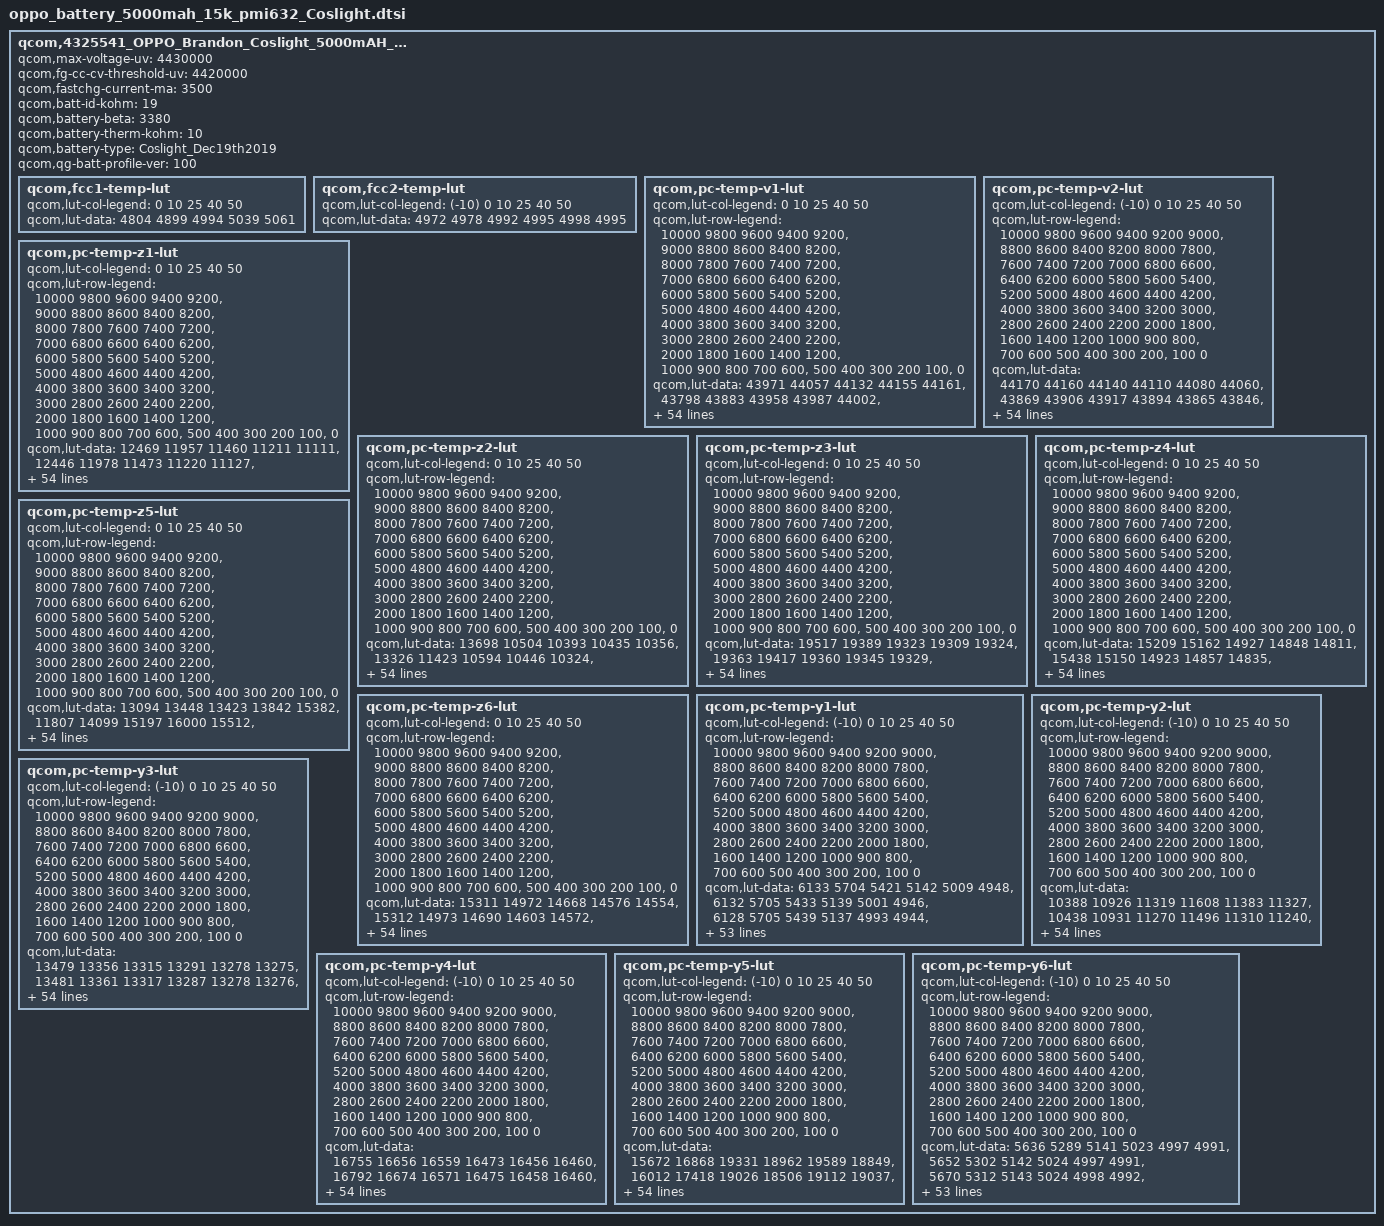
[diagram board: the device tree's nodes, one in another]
qcom,4325541_OPPO_Brandon_Coslight_5000mAH_PMI632 {
    /* 4325541_OPPO_Brandon_Coslight_5000mAH_PMI632_averaged_MasterSlave_Dec19th2019 */
    qcom,max-voltage-uv = <4430000>;
    qcom,fg-cc-cv-threshold-uv = <4420000>;
    qcom,fastchg-current-ma = <3500>;
    qcom,batt-id-kohm = <19>;
    qcom,battery-beta = <3380>;
    qcom,battery-therm-kohm = <10>;
    qcom,battery-type = "Coslight_Dec19th2019";
    qcom,qg-batt-profile-ver = <100>;

	qcom,fcc1-temp-lut {
		qcom,lut-col-legend = <0 10 25 40 50>;
		qcom,lut-data = <4804 4899 4994 5039 5061>;
	};

	qcom,fcc2-temp-lut {
		qcom,lut-col-legend = <(-10) 0 10 25 40 50>;
		qcom,lut-data = <4972 4978 4992 4995 4998 4995>;
	};

	qcom,pc-temp-v1-lut {
		qcom,lut-col-legend = <0 10 25 40 50>;
		qcom,lut-row-legend = <10000 9800 9600 9400 9200>,
			<9000 8800 8600 8400 8200>,
			<8000 7800 7600 7400 7200>,
			<7000 6800 6600 6400 6200>,
			<6000 5800 5600 5400 5200>,
			<5000 4800 4600 4400 4200>,
			<4000 3800 3600 3400 3200>,
			<3000 2800 2600 2400 2200>,
			<2000 1800 1600 1400 1200>,
			<1000 900 800 700 600>,
			<500 400 300 200 100>,
			<0>;
		qcom,lut-data = <43971 44057 44132 44155 44161>,
			<43798 43883 43958 43987 44002>,
			<43566 43688 43770 43806 43822>,
			<43320 43475 43569 43614 43628>,
			<43084 43249 43353 43404 43424>,
			<42847 43013 43128 43181 43208>,
			<42612 42767 42894 42952 42982>,
			<42376 42525 42653 42714 42747>,
			<42143 42286 42413 42475 42509>,
			<41914 42050 42172 42235 42269>,
			<41688 41818 41934 41996 42030>,
			<41469 41591 41699 41760 41793>,
			<41257 41370 41470 41529 41559>,
			<41051 41160 41247 41302 41329>,
			<40843 40952 41031 41081 41105>,
			<40632 40743 40822 40867 40886>,
			<40428 40535 40616 40661 40680>,
			<40241 40339 40416 40461 40482>,
			<40065 40167 40225 40266 40289>,
			<39887 39991 40046 40084 40103>,
			<39713 39756 39848 39894 39912>,
			<39534 39448 39584 39652 39680>,
			<39324 39205 39308 39372 39407>,
			<39077 39063 39124 39163 39189>,
			<38891 38952 38994 39022 39041>,
			<38794 38848 38878 38901 38918>,
			<38723 38754 38761 38781 38797>,
			<38655 38666 38653 38668 38684>,
			<38590 38581 38557 38567 38579>,
			<38530 38501 38468 38474 38479>,
			<38475 38430 38389 38390 38388>,
			<38424 38365 38318 38311 38305>,
			<38377 38308 38254 38238 38228>,
			<38336 38258 38195 38169 38155>,
			<38298 38213 38141 38107 38084>,
			<38259 38170 38090 38045 38013>,
			<38220 38132 38043 37985 37944>,
			<38173 38088 37994 37925 37874>,
			<38101 38019 37925 37847 37790>,
			<38007 37920 37825 37745 37684>,
			<37898 37809 37713 37629 37567>,
			<37762 37681 37595 37509 37442>,
			<37613 37537 37463 37377 37306>,
			<37445 37370 37301 37219 37151>,
			<37302 37230 37162 37088 37030>,
			<37213 37141 37076 37014 36957>,
			<37188 37120 37054 36990 36935>,
			<37168 37103 37038 36973 36919>,
			<37136 37080 37023 36956 36896>,
			<37076 37025 36959 36877 36805>,
			<36839 36769 36675 36569 36481>,
			<36378 36311 36224 36117 36027>,
			<35790 35723 35638 35532 35441>,
			<34987 34916 34832 34728 34635>,
			<33702 33635 33569 33469 33375>,
			<30000 30000 30000 30000 30000>;
	};

	qcom,pc-temp-v2-lut {
		qcom,lut-col-legend = <(-10) 0 10 25 40 50>;
		qcom,lut-row-legend = <10000 9800 9600 9400 9200 9000>,
			<8800 8600 8400 8200 8000 7800>,
			<7600 7400 7200 7000 6800 6600>,
			<6400 6200 6000 5800 5600 5400>,
			<5200 5000 4800 4600 4400 4200>,
			<4000 3800 3600 3400 3200 3000>,
			<2800 2600 2400 2200 2000 1800>,
			<1600 1400 1200 1000 900 800>,
			<700 600 500 400 300 200>,
			<100 0>;
		qcom,lut-data = <44170 44160 44140 44110 44080 44060>,
			<43869 43906 43917 43894 43865 43846>,
			<43589 43659 43692 43676 43649 43631>,
			<43330 43422 43469 43457 43433 43416>,
			<43095 43194 43247 43237 43216 43201>,
			<42861 42964 43019 43012 42994 42980>,
			<42615 42721 42782 42776 42760 42748>,
			<42368 42473 42539 42535 42521 42509>,
			<42136 42229 42298 42296 42282 42272>,
			<41922 41985 42055 42057 42043 42033>,
			<41698 41749 41817 41822 41806 41797>,
			<41431 41522 41583 41587 41572 41564>,
			<41154 41302 41354 41357 41343 41335>,
			<40938 41092 41132 41131 41118 41111>,
			<40783 40893 40917 40911 40898 40891>,
			<40602 40684 40706 40698 40685 40679>,
			<40291 40446 40501 40494 40482 40477>,
			<39905 40190 40294 40294 40285 40281>,
			<39624 39935 40060 40094 40091 40089>,
			<39425 39672 39789 39895 39905 39904>,
			<39236 39428 39533 39682 39703 39704>,
			<39016 39219 39311 39426 39445 39450>,
			<38794 39032 39111 39164 39177 39184>,
			<38613 38862 38938 38969 38982 38990>,
			<38460 38708 38788 38819 38834 38842>,
			<38337 38568 38653 38689 38705 38712>,
			<38248 38439 38529 38568 38584 38590>,
			<38178 38320 38415 38458 38474 38479>,
			<38115 38207 38311 38357 38374 38377>,
			<38058 38093 38213 38263 38281 38281>,
			<38005 38003 38122 38177 38196 38193>,
			<37951 37945 38032 38096 38121 38117>,
			<37899 37900 37949 38020 38049 38044>,
			<37843 37860 37880 37948 37971 37962>,
			<37785 37825 37823 37881 37889 37870>,
			<37724 37786 37771 37810 37800 37772>,
			<37657 37734 37723 37731 37698 37663>,
			<37585 37668 37676 37647 37590 37549>,
			<37504 37591 37614 37563 37494 37449>,
			<37407 37501 37534 37482 37409 37362>,
			<37307 37397 37438 37393 37319 37270>,
			<37209 37269 37318 37285 37213 37163>,
			<37113 37130 37182 37164 37098 37045>,
			<37020 37014 37042 37023 36960 36904>,
			<36932 36912 36927 36921 36872 36818>,
			<36842 36827 36852 36878 36834 36783>,
			<36786 36784 36821 36860 36824 36773>,
			<36719 36720 36792 36841 36807 36756>,
			<36624 36628 36739 36812 36774 36721>,
			<36493 36488 36633 36720 36655 36571>,
			<36295 36249 36359 36403 36285 36186>,
			<35945 35870 35878 35902 35770 35670>,
			<35365 35295 35201 35236 35098 34990>,
			<34502 34434 34287 34328 34151 34042>,
			<33097 32984 32797 32911 32702 32622>,
			<28862 28432 27905 27825 27876 27931>;
	};

	qcom,pc-temp-z1-lut {
		qcom,lut-col-legend = <0 10 25 40 50>;
		qcom,lut-row-legend = <10000 9800 9600 9400 9200>,
			<9000 8800 8600 8400 8200>,
			<8000 7800 7600 7400 7200>,
			<7000 6800 6600 6400 6200>,
			<6000 5800 5600 5400 5200>,
			<5000 4800 4600 4400 4200>,
			<4000 3800 3600 3400 3200>,
			<3000 2800 2600 2400 2200>,
			<2000 1800 1600 1400 1200>,
			<1000 900 800 700 600>,
			<500 400 300 200 100>,
			<0>;
		qcom,lut-data = <12469 11957 11460 11211 11111>,
			<12446 11978 11473 11220 11127>,
			<12471 11982 11479 11224 11135>,
			<12493 11978 11479 11224 11138>,
			<12490 11973 11471 11223 11138>,
			<12479 11963 11463 11220 11137>,
			<12473 11948 11455 11217 11136>,
			<12460 11935 11446 11212 11133>,
			<12444 11924 11438 11208 11130>,
			<12426 11913 11431 11206 11130>,
			<12394 11899 11426 11205 11130>,
			<12370 11884 11424 11203 11129>,
			<12360 11875 11423 11202 11127>,
			<12353 11871 11422 11201 11127>,
			<12344 11867 11421 11200 11127>,
			<12334 11863 11420 11200 11127>,
			<12325 11858 11420 11200 11127>,
			<12323 11856 11419 11199 11127>,
			<12323 11855 11420 11199 11127>,
			<12324 11854 11421 11200 11128>,
			<12322 11856 11422 11201 11130>,
			<12319 11861 11423 11201 11130>,
			<12320 11866 11425 11202 11129>,
			<12325 11869 11428 11203 11129>,
			<12328 11872 11432 11205 11131>,
			<12330 11874 11437 11207 11133>,
			<12332 11877 11442 11211 11136>,
			<12333 11879 11447 11214 11140>,
			<12335 11881 11452 11218 11143>,
			<12337 11886 11456 11222 11146>,
			<12341 11888 11459 11226 11149>,
			<12348 11894 11464 11229 11153>,
			<12353 11899 11470 11233 11157>,
			<12361 11900 11474 11237 11161>,
			<12369 11902 11479 11241 11164>,
			<12374 11904 11484 11246 11167>,
			<12377 11909 11488 11249 11170>,
			<12382 11916 11492 11253 11174>,
			<12395 11925 11497 11256 11177>,
			<12411 11936 11504 11261 11180>,
			<12419 11946 11512 11266 11183>,
			<12425 11956 11520 11270 11187>,
			<12431 11967 11528 11275 11190>,
			<12438 11980 11536 11279 11191>,
			<12469 12000 11548 11285 11196>,
			<12470 11990 11559 11289 11197>,
			<12475 11994 11555 11290 11199>,
			<12472 11995 11560 11290 11200>,
			<12463 11996 11563 11294 11203>,
			<12479 12000 11574 11300 11208>,
			<12488 12027 11579 11306 11215>,
			<12499 12033 11586 11315 11219>,
			<12510 12034 11597 11322 11228>,
			<12527 12064 11611 11338 11242>,
			<12527 12064 11611 11338 11242>,
			<12527 12064 11611 11338 11242>;
	};

	qcom,pc-temp-z2-lut {
		qcom,lut-col-legend = <0 10 25 40 50>;
		qcom,lut-row-legend = <10000 9800 9600 9400 9200>,
			<9000 8800 8600 8400 8200>,
			<8000 7800 7600 7400 7200>,
			<7000 6800 6600 6400 6200>,
			<6000 5800 5600 5400 5200>,
			<5000 4800 4600 4400 4200>,
			<4000 3800 3600 3400 3200>,
			<3000 2800 2600 2400 2200>,
			<2000 1800 1600 1400 1200>,
			<1000 900 800 700 600>,
			<500 400 300 200 100>,
			<0>;
		qcom,lut-data = <13698 10504 10393 10435 10356>,
			<13326 11423 10594 10446 10324>,
			<11592 11584 10717 10457 10394>,
			<10391 11326 10726 10463 10451>,
			<10299 11020 10685 10497 10433>,
			<10277 10768 10642 10539 10387>,
			<10260 10526 10602 10527 10339>,
			<10242 10437 10561 10473 10270>,
			<10228 10407 10531 10429 10215>,
			<10218 10392 10503 10407 10188>,
			<10209 10392 10490 10386 10168>,
			<10204 10393 10502 10345 10169>,
			<10207 10397 10525 10280 10192>,
			<10213 10422 10542 10254 10211>,
			<10221 10456 10556 10267 10229>,
			<10234 10477 10573 10288 10252>,
			<10252 10494 10612 10310 10260>,
			<10277 10509 10656 10334 10265>,
			<10310 10522 10670 10355 10277>,
			<10332 10537 10671 10370 10325>,
			<10343 10565 10675 10391 10390>,
			<10352 10618 10721 10497 10425>,
			<10366 10645 10785 10723 10451>,
			<10387 10619 10803 10800 10479>,
			<10399 10579 10803 10725 10516>,
			<10400 10573 10802 10646 10552>,
			<10400 10585 10804 10657 10563>,
			<10401 10597 10805 10718 10550>,
			<10407 10605 10796 10721 10541>,
			<10414 10610 10761 10649 10512>,
			<10421 10615 10738 10584 10466>,
			<10430 10620 10736 10568 10412>,
			<10435 10627 10737 10558 10345>,
			<10438 10636 10746 10556 10324>,
			<10440 10649 10783 10558 10340>,
			<10442 10660 10818 10561 10369>,
			<10449 10668 10835 10587 10416>,
			<10453 10677 10852 10655 10490>,
			<10452 10690 10880 10746 10564>,
			<10449 10708 10935 10911 10688>,
			<10446 10715 10966 11018 10785>,
			<10436 10702 10957 10966 10826>,
			<10432 10689 10943 10883 10854>,
			<10441 10682 10932 10881 10751>,
			<10580 10780 10941 10814 10644>,
			<10591 10836 10931 10726 10549>,
			<10511 10796 10944 10640 10585>,
			<10312 10720 10893 10671 10558>,
			<10311 10735 10839 10717 10632>,
			<10278 10722 10910 10839 10699>,
			<10300 10726 10906 10660 10431>,
			<10184 10666 10796 10370 10199>,
			<10022 10589 10796 10323 10181>,
			<9865 10479 10703 10227 10094>,
			<9865 10479 10703 10227 10094>,
			<9865 10479 10703 10227 10094>;
	};

	qcom,pc-temp-z3-lut {
		qcom,lut-col-legend = <0 10 25 40 50>;
		qcom,lut-row-legend = <10000 9800 9600 9400 9200>,
			<9000 8800 8600 8400 8200>,
			<8000 7800 7600 7400 7200>,
			<7000 6800 6600 6400 6200>,
			<6000 5800 5600 5400 5200>,
			<5000 4800 4600 4400 4200>,
			<4000 3800 3600 3400 3200>,
			<3000 2800 2600 2400 2200>,
			<2000 1800 1600 1400 1200>,
			<1000 900 800 700 600>,
			<500 400 300 200 100>,
			<0>;
		qcom,lut-data = <19517 19389 19323 19309 19324>,
			<19363 19417 19360 19345 19329>,
			<19500 19440 19389 19359 19348>,
			<19629 19475 19407 19369 19366>,
			<19655 19502 19420 19382 19374>,
			<19668 19513 19426 19394 19380>,
			<19672 19520 19426 19397 19384>,
			<19671 19522 19426 19398 19387>,
			<19669 19522 19426 19398 19388>,
			<19668 19521 19425 19395 19387>,
			<19668 19519 19425 19391 19383>,
			<19666 19516 19421 19387 19380>,
			<19660 19512 19415 19380 19377>,
			<19650 19500 19410 19375 19374>,
			<19648 19489 19403 19370 19372>,
			<19652 19488 19400 19366 19369>,
			<19654 19488 19399 19363 19365>,
			<19644 19488 19398 19362 19358>,
			<19617 19483 19396 19360 19354>,
			<19606 19477 19393 19357 19352>,
			<19621 19483 19391 19355 19350>,
			<19640 19511 19398 19357 19350>,
			<19647 19527 19407 19362 19351>,
			<19651 19516 19408 19364 19351>,
			<19653 19499 19400 19360 19352>,
			<19647 19495 19394 19357 19354>,
			<19635 19495 19402 19364 19359>,
			<19629 19495 19414 19381 19372>,
			<19625 19499 19417 19387 19379>,
			<19622 19505 19418 19383 19380>,
			<19621 19507 19417 19379 19380>,
			<19620 19506 19414 19377 19377>,
			<19618 19504 19410 19375 19371>,
			<19616 19502 19408 19371 19365>,
			<19613 19499 19405 19366 19356>,
			<19612 19496 19403 19360 19350>,
			<19610 19493 19398 19355 19346>,
			<19608 19489 19394 19351 19344>,
			<19602 19486 19393 19350 19343>,
			<19593 19481 19392 19353 19344>,
			<19587 19477 19392 19355 19345>,
			<19583 19474 19389 19356 19351>,
			<19576 19470 19385 19357 19357>,
			<19558 19460 19379 19357 19356>,
			<19497 19430 19367 19352 19350>,
			<19463 19417 19360 19335 19335>,
			<19418 19401 19358 19332 19326>,
			<19351 19371 19352 19332 19320>,
			<19345 19344 19329 19319 19314>,
			<19341 19332 19329 19321 19316>,
			<19342 19337 19336 19348 19345>,
			<19343 19331 19339 19355 19348>,
			<19341 19319 19328 19345 19343>,
			<19340 19320 19336 19341 19340>,
			<19340 19320 19336 19341 19340>,
			<19340 19320 19336 19341 19340>;
	};

	qcom,pc-temp-z4-lut {
		qcom,lut-col-legend = <0 10 25 40 50>;
		qcom,lut-row-legend = <10000 9800 9600 9400 9200>,
			<9000 8800 8600 8400 8200>,
			<8000 7800 7600 7400 7200>,
			<7000 6800 6600 6400 6200>,
			<6000 5800 5600 5400 5200>,
			<5000 4800 4600 4400 4200>,
			<4000 3800 3600 3400 3200>,
			<3000 2800 2600 2400 2200>,
			<2000 1800 1600 1400 1200>,
			<1000 900 800 700 600>,
			<500 400 300 200 100>,
			<0>;
		qcom,lut-data = <15209 15162 14927 14848 14811>,
			<15438 15150 14923 14857 14835>,
			<15383 15122 14914 14848 14828>,
			<15306 15057 14898 14836 14818>,
			<15228 14991 14862 14815 14804>,
			<15140 14948 14828 14789 14784>,
			<15070 14912 14806 14770 14767>,
			<15018 14881 14786 14754 14751>,
			<14974 14852 14767 14740 14737>,
			<14936 14827 14749 14724 14724>,
			<14901 14805 14734 14712 14712>,
			<14874 14785 14724 14709 14705>,
			<14853 14772 14717 14706 14701>,
			<14836 14763 14712 14704 14697>,
			<14819 14757 14708 14701 14693>,
			<14797 14753 14705 14697 14690>,
			<14784 14750 14700 14692 14686>,
			<14788 14747 14695 14685 14683>,
			<14799 14741 14694 14683 14681>,
			<14804 14737 14696 14684 14682>,
			<14788 14749 14699 14687 14684>,
			<14770 14799 14739 14713 14703>,
			<14784 14834 14797 14776 14766>,
			<14847 14843 14808 14799 14797>,
			<14887 14849 14807 14796 14790>,
			<14885 14848 14805 14791 14778>,
			<14879 14835 14791 14775 14761>,
			<14873 14820 14767 14745 14736>,
			<14863 14805 14752 14727 14717>,
			<14852 14790 14741 14719 14705>,
			<14843 14781 14733 14712 14695>,
			<14834 14776 14727 14704 14689>,
			<14825 14771 14723 14696 14683>,
			<14817 14769 14720 14694 14682>,
			<14810 14767 14718 14694 14683>,
			<14804 14765 14717 14694 14684>,
			<14798 14762 14717 14694 14685>,
			<14792 14760 14716 14695 14685>,
			<14787 14758 14717 14696 14687>,
			<14782 14756 14723 14703 14696>,
			<14774 14752 14726 14708 14704>,
			<14762 14741 14720 14704 14698>,
			<14748 14728 14711 14698 14688>,
			<14735 14718 14707 14697 14692>,
			<14707 14690 14689 14686 14684>,
			<14715 14674 14670 14674 14671>,
			<14759 14679 14660 14669 14670>,
			<14828 14703 14653 14654 14659>,
			<14830 14726 14662 14646 14642>,
			<14829 14737 14660 14637 14633>,
			<14829 14742 14678 14647 14649>,
			<14841 14758 14682 14650 14656>,
			<14851 14773 14695 14660 14662>,
			<14863 14776 14686 14666 14665>,
			<14863 14776 14686 14666 14665>,
			<14863 14776 14686 14666 14665>;
	};

	qcom,pc-temp-z5-lut {
		qcom,lut-col-legend = <0 10 25 40 50>;
		qcom,lut-row-legend = <10000 9800 9600 9400 9200>,
			<9000 8800 8600 8400 8200>,
			<8000 7800 7600 7400 7200>,
			<7000 6800 6600 6400 6200>,
			<6000 5800 5600 5400 5200>,
			<5000 4800 4600 4400 4200>,
			<4000 3800 3600 3400 3200>,
			<3000 2800 2600 2400 2200>,
			<2000 1800 1600 1400 1200>,
			<1000 900 800 700 600>,
			<500 400 300 200 100>,
			<0>;
		qcom,lut-data = <13094 13448 13423 13842 15382>,
			<11807 14099 15197 16000 15512>,
			<13612 14640 16588 16805 17064>,
			<15521 15407 17483 17483 18517>,
			<16260 16215 18159 18634 19230>,
			<16744 16988 18568 19808 19850>,
			<17179 17811 18753 20291 20413>,
			<17602 18407 18912 20649 20964>,
			<18065 18917 19224 20867 21529>,
			<18730 19480 19902 21457 22190>,
			<19678 20278 20600 22114 22884>,
			<20479 21216 21210 22120 23419>,
			<20989 21603 21782 21813 23838>,
			<21539 21654 22153 21673 24320>,
			<22735 21704 22275 21660 25319>,
			<26503 22391 22417 21797 26346>,
			<29510 24275 23364 22469 26369>,
			<28273 25150 24725 23718 25772>,
			<24894 24614 25273 24497 25449>,
			<23722 23950 25478 24945 26588>,
			<30472 27576 25779 25228 28085>,
			<39765 42562 27216 24998 27527>,
			<44506 51304 29046 24114 24379>,
			<47867 43689 28467 23009 21555>,
			<49305 31990 23814 20305 19385>,
			<45493 28329 20814 18041 17911>,
			<38731 27146 21791 18901 18362>,
			<35608 26676 23646 21352 20404>,
			<34198 27819 25056 22586 22206>,
			<33499 30321 26454 22892 24048>,
			<33714 32385 27778 23215 25796>,
			<34401 34215 28894 24300 26875>,
			<35000 35718 29943 26052 27714>,
			<35758 36821 31215 27033 28076>,
			<36465 37750 33026 27576 27926>,
			<36982 38165 33987 27841 27725>,
			<38380 38244 33645 27697 27885>,
			<39246 38171 32974 27397 28195>,
			<38784 37822 32472 27343 28191>,
			<38006 37075 32102 27589 27171>,
			<37776 36517 31586 27777 26309>,
			<37458 36259 30208 27095 27209>,
			<36710 35795 28332 25973 28531>,
			<34352 33675 26283 25593 27843>,
			<30656 33053 26586 25413 26087>,
			<23675 32735 27458 21549 21268>,
			<17903 25194 27611 21224 19273>,
			<13204 18941 26512 23749 19190>,
			<13022 15270 19344 22297 21774>,
			<12977 14472 19352 23973 24935>,
			<13121 14733 18310 27173 27209>,
			<12911 13916 17407 25373 24224>,
			<12635 13203 15273 19867 19916>,
			<12381 13033 15874 17650 17728>,
			<12381 13033 15874 17650 17728>,
			<12381 13033 15874 17650 17728>;
	};

	qcom,pc-temp-z6-lut {
		qcom,lut-col-legend = <0 10 25 40 50>;
		qcom,lut-row-legend = <10000 9800 9600 9400 9200>,
			<9000 8800 8600 8400 8200>,
			<8000 7800 7600 7400 7200>,
			<7000 6800 6600 6400 6200>,
			<6000 5800 5600 5400 5200>,
			<5000 4800 4600 4400 4200>,
			<4000 3800 3600 3400 3200>,
			<3000 2800 2600 2400 2200>,
			<2000 1800 1600 1400 1200>,
			<1000 900 800 700 600>,
			<500 400 300 200 100>,
			<0>;
		qcom,lut-data = <15311 14972 14668 14576 14554>,
			<15312 14973 14690 14603 14572>,
			<15320 14965 14702 14610 14582>,
			<15325 14945 14701 14612 14589>,
			<15305 14922 14691 14609 14587>,
			<15249 14901 14679 14603 14582>,
			<15200 14881 14668 14598 14578>,
			<15165 14862 14658 14591 14573>,
			<15134 14843 14649 14585 14567>,
			<15107 14826 14640 14577 14561>,
			<15084 14811 14632 14570 14554>,
			<15063 14798 14624 14564 14549>,
			<15044 14786 14618 14559 14545>,
			<15026 14775 14612 14555 14542>,
			<15012 14766 14607 14550 14538>,
			<15001 14762 14603 14546 14535>,
			<14991 14760 14600 14542 14530>,
			<14983 14758 14597 14538 14525>,
			<14975 14753 14596 14536 14522>,
			<14972 14748 14596 14535 14521>,
			<14974 14757 14595 14535 14521>,
			<14977 14796 14616 14546 14528>,
			<14989 14818 14647 14577 14556>,
			<15020 14816 14652 14588 14570>,
			<15038 14813 14650 14586 14568>,
			<15035 14809 14647 14582 14564>,
			<15028 14805 14644 14579 14561>,
			<15023 14801 14642 14576 14557>,
			<15019 14799 14639 14573 14553>,
			<15015 14797 14635 14568 14550>,
			<15012 14795 14632 14563 14546>,
			<15009 14793 14629 14560 14542>,
			<15006 14792 14625 14556 14537>,
			<15004 14791 14624 14553 14533>,
			<15001 14790 14623 14550 14530>,
			<15001 14789 14622 14548 14527>,
			<15001 14788 14620 14546 14525>,
			<15001 14788 14618 14544 14524>,
			<15001 14788 14619 14544 14524>,
			<15001 14789 14622 14549 14528>,
			<15002 14789 14625 14552 14532>,
			<15002 14787 14622 14551 14532>,
			<15002 14783 14617 14550 14532>,
			<14998 14780 14615 14550 14533>,
			<14974 14764 14604 14544 14528>,
			<14965 14754 14595 14531 14514>,
			<14962 14750 14589 14526 14510>,
			<14958 14746 14584 14520 14502>,
			<14959 14743 14577 14510 14491>,
			<14961 14746 14578 14508 14489>,
			<14970 14756 14592 14528 14512>,
			<14983 14764 14597 14535 14521>,
			<14995 14772 14601 14537 14524>,
			<15014 14784 14607 14542 14527>,
			<15014 14784 14607 14542 14527>,
			<15014 14784 14607 14542 14527>;
	};

	qcom,pc-temp-y1-lut {
		qcom,lut-col-legend = <(-10) 0 10 25 40 50>;
		qcom,lut-row-legend = <10000 9800 9600 9400 9200 9000>,
			<8800 8600 8400 8200 8000 7800>,
			<7600 7400 7200 7000 6800 6600>,
			<6400 6200 6000 5800 5600 5400>,
			<5200 5000 4800 4600 4400 4200>,
			<4000 3800 3600 3400 3200 3000>,
			<2800 2600 2400 2200 2000 1800>,
			<1600 1400 1200 1000 900 800>,
			<700 600 500 400 300 200>,
			<100 0>;
		qcom,lut-data = <6133 5704 5421 5142 5009 4948>,
			<6132 5705 5433 5139 5001 4946>,
			<6128 5705 5439 5137 4993 4944>,
			<6124 5705 5440 5133 4987 4942>,
			<6120 5706 5439 5130 4982 4940>,
			<6117 5706 5436 5127 4980 4938>,
			<6111 5707 5429 5125 4981 4935>,
			<6101 5708 5420 5122 4983 4933>,
			<6102 5707 5414 5121 4983 4933>,
			<6118 5704 5410 5119 4982 4935>,
			<6129 5700 5408 5118 4982 4936>,
			<6127 5698 5406 5117 4980 4935>,
			<6122 5696 5405 5115 4979 4934>,
			<6123 5695 5403 5115 4978 4934>,
			<6133 5694 5400 5115 4977 4935>,
			<6140 5693 5398 5115 4977 4936>,
			<6134 5692 5400 5115 4977 4936>,
			<6122 5692 5403 5115 4978 4935>,
			<6120 5692 5403 5115 4979 4935>,
			<6130 5697 5401 5116 4981 4936>,
			<6137 5700 5400 5118 4982 4936>,
			<6129 5701 5401 5119 4982 4936>,
			<6113 5701 5403 5122 4982 4936>,
			<6108 5701 5404 5125 4983 4937>,
			<6115 5698 5405 5128 4985 4938>,
			<6121 5697 5406 5131 4987 4940>,
			<6115 5703 5407 5135 4988 4940>,
			<6105 5712 5411 5139 4989 4941>,
			<6103 5716 5415 5142 4991 4942>,
			<6119 5716 5422 5144 4993 4945>,
			<6133 5714 5427 5146 4997 4948>,
			<6125 5712 5428 5152 5000 4950>,
			<6107 5711 5429 5159 5004 4953>,
			<6101 5710 5430 5163 5007 4955>,
			<6095 5705 5435 5165 5010 4959>,
			<6091 5701 5438 5167 5012 4961>,
			<6090 5707 5439 5171 5015 4963>,
			<6089 5720 5440 5176 5017 4964>,
			<6088 5724 5442 5179 5018 4966>,
			<6089 5718 5445 5180 5019 4968>,
			<6089 5711 5449 5183 5020 4970>,
			<6090 5708 5463 5188 5024 4971>,
			<6093 5704 5476 5194 5029 4973>,
			<6096 5710 5470 5195 5031 4976>,
			<6097 5714 5465 5199 5035 4978>,
			<6101 5726 5475 5203 5040 4982>,
			<6145 5729 5473 5207 5038 4981>,
			<6149 5722 5478 5208 5036 4980>,
			<6129 5732 5482 5210 5036 4981>,
			<6128 5745 5473 5209 5037 4983>,
			<6167 5737 5478 5212 5039 4986>,
			<6208 5739 5485 5222 5046 4990>,
			<6259 5778 5493 5233 5054 4996>,
			<6345 5816 5514 5249 5060 5003>,
			<6345 5816 5514 5249 5060 5003>,
			<6345 5816 5514 5249 5060 5003>;
	};

	qcom,pc-temp-y2-lut {
		qcom,lut-col-legend = <(-10) 0 10 25 40 50>;
		qcom,lut-row-legend = <10000 9800 9600 9400 9200 9000>,
			<8800 8600 8400 8200 8000 7800>,
			<7600 7400 7200 7000 6800 6600>,
			<6400 6200 6000 5800 5600 5400>,
			<5200 5000 4800 4600 4400 4200>,
			<4000 3800 3600 3400 3200 3000>,
			<2800 2600 2400 2200 2000 1800>,
			<1600 1400 1200 1000 900 800>,
			<700 600 500 400 300 200>,
			<100 0>;
		qcom,lut-data = <10388 10926 11319 11608 11383 11327>,
			<10438 10931 11270 11496 11310 11240>,
			<10488 10924 11221 11381 11212 11137>,
			<10535 10912 11175 11279 11112 11033>,
			<10576 10898 11133 11203 11030 10946>,
			<10607 10889 11097 11169 10990 10894>,
			<10633 10879 11063 11182 10986 10872>,
			<10652 10867 11035 11207 10988 10858>,
			<10654 10868 11026 11202 10972 10836>,
			<10645 10884 11022 11166 10920 10799>,
			<10639 10901 11021 11141 10887 10774>,
			<10716 10908 11036 11150 10887 10781>,
			<10849 10914 11068 11167 10889 10796>,
			<10866 10946 11102 11168 10895 10799>,
			<10776 11079 11140 11156 10922 10798>,
			<10709 11173 11188 11148 10949 10797>,
			<10744 11160 11282 11198 10975 10833>,
			<10810 11137 11382 11305 11021 10913>,
			<10828 11133 11400 11421 11119 11014>,
			<10827 11148 11392 11576 11366 11168>,
			<10825 11159 11383 11660 11516 11266>,
			<10533 11157 11380 11619 11423 11262>,
			<9962 11153 11382 11547 11276 11240>,
			<9771 11153 11390 11513 11255 11249>,
			<9744 11162 11411 11497 11298 11293>,
			<9726 11169 11428 11496 11352 11336>,
			<9710 11151 11436 11557 11406 11360>,
			<9696 11113 11443 11647 11461 11385>,
			<9688 11088 11447 11667 11517 11426>,
			<9683 11073 11453 11660 11612 11495>,
			<9680 11057 11455 11656 11688 11562>,
			<9677 11027 11443 11698 11750 11633>,
			<9674 10984 11420 11762 11811 11704>,
			<9672 10945 11397 11771 11811 11731>,
			<9670 10913 11371 11745 11746 11763>,
			<9668 10865 11346 11712 11666 11767>,
			<9667 10615 11321 11671 11563 11659>,
			<9666 10152 11289 11628 11459 11498>,
			<9664 9906 11246 11603 11438 11439>,
			<9663 9785 11176 11577 11438 11428>,
			<9663 9715 11096 11563 11438 11428>,
			<9662 9695 11016 11547 11444 11407>,
			<9661 9685 10923 11517 11442 11355>,
			<9660 9679 10811 11452 11337 11185>,
			<9658 9673 10465 11357 11161 10951>,
			<9657 9669 10218 11298 11059 10917>,
			<9657 9667 10170 11321 11092 10921>,
			<9656 9665 10320 11271 11120 10954>,
			<9655 9663 10308 11318 11189 11030>,
			<9654 9661 10481 11335 11169 10939>,
			<9652 9659 9965 11252 11080 10866>,
			<9650 9656 9768 11155 10934 10777>,
			<9649 9653 9689 11036 10906 10711>,
			<9649 9651 9665 10950 10719 10616>,
			<9649 9651 9665 10950 10719 10616>,
			<9649 9651 9665 10950 10719 10616>;
	};

	qcom,pc-temp-y3-lut {
		qcom,lut-col-legend = <(-10) 0 10 25 40 50>;
		qcom,lut-row-legend = <10000 9800 9600 9400 9200 9000>,
			<8800 8600 8400 8200 8000 7800>,
			<7600 7400 7200 7000 6800 6600>,
			<6400 6200 6000 5800 5600 5400>,
			<5200 5000 4800 4600 4400 4200>,
			<4000 3800 3600 3400 3200 3000>,
			<2800 2600 2400 2200 2000 1800>,
			<1600 1400 1200 1000 900 800>,
			<700 600 500 400 300 200>,
			<100 0>;
		qcom,lut-data = <13479 13356 13315 13291 13278 13275>,
			<13481 13361 13317 13287 13278 13276>,
			<13484 13367 13319 13285 13278 13277>,
			<13486 13372 13321 13284 13279 13278>,
			<13488 13376 13323 13284 13280 13279>,
			<13489 13379 13325 13284 13280 13280>,
			<13490 13381 13327 13285 13281 13280>,
			<13490 13382 13329 13286 13283 13281>,
			<13491 13382 13330 13289 13284 13281>,
			<13495 13382 13330 13293 13285 13282>,
			<13498 13382 13330 13295 13285 13283>,
			<13479 13382 13330 13296 13286 13283>,
			<13447 13383 13331 13297 13286 13284>,
			<13439 13382 13331 13297 13287 13285>,
			<13440 13376 13330 13296 13287 13285>,
			<13441 13371 13330 13295 13287 13286>,
			<13436 13370 13330 13297 13288 13287>,
			<13427 13369 13329 13300 13290 13290>,
			<13420 13366 13328 13301 13292 13291>,
			<13416 13358 13324 13301 13293 13291>,
			<13411 13350 13318 13300 13294 13291>,
			<13402 13346 13314 13296 13288 13286>,
			<13393 13343 13310 13288 13280 13278>,
			<13390 13341 13308 13286 13278 13277>,
			<13390 13338 13307 13284 13278 13277>,
			<13391 13336 13306 13284 13279 13278>,
			<13396 13335 13305 13284 13278 13278>,
			<13408 13334 13305 13284 13277 13277>,
			<13422 13331 13305 13284 13276 13277>,
			<13441 13321 13304 13284 13276 13276>,
			<13464 13313 13304 13284 13277 13275>,
			<13490 13315 13303 13284 13277 13275>,
			<13522 13319 13302 13284 13278 13276>,
			<13559 13324 13302 13284 13278 13276>,
			<13604 13330 13302 13284 13278 13277>,
			<13656 13337 13303 13284 13278 13277>,
			<13713 13340 13304 13284 13277 13277>,
			<13778 13344 13306 13284 13276 13276>,
			<13846 13350 13308 13284 13276 13277>,
			<13918 13368 13310 13285 13277 13278>,
			<13994 13392 13312 13285 13278 13279>,
			<14072 13415 13313 13286 13280 13279>,
			<14155 13443 13315 13286 13281 13279>,
			<14254 13484 13317 13286 13278 13277>,
			<14373 13544 13320 13287 13280 13279>,
			<14465 13598 13319 13289 13282 13282>,
			<14514 13635 13324 13291 13287 13285>,
			<14661 13703 13337 13295 13289 13286>,
			<14843 13794 13350 13301 13291 13288>,
			<15182 13912 13364 13303 13289 13284>,
			<15958 14083 13376 13297 13285 13282>,
			<17574 14379 13404 13299 13285 13283>,
			<21263 15116 13487 13301 13289 13285>,
			<29967 17239 13794 13313 13294 13294>,
			<29967 17239 13794 13313 13294 13294>,
			<29967 17239 13794 13313 13294 13294>;
	};

	qcom,pc-temp-y4-lut {
		qcom,lut-col-legend = <(-10) 0 10 25 40 50>;
		qcom,lut-row-legend = <10000 9800 9600 9400 9200 9000>,
			<8800 8600 8400 8200 8000 7800>,
			<7600 7400 7200 7000 6800 6600>,
			<6400 6200 6000 5800 5600 5400>,
			<5200 5000 4800 4600 4400 4200>,
			<4000 3800 3600 3400 3200 3000>,
			<2800 2600 2400 2200 2000 1800>,
			<1600 1400 1200 1000 900 800>,
			<700 600 500 400 300 200>,
			<100 0>;
		qcom,lut-data = <16755 16656 16559 16473 16456 16460>,
			<16792 16674 16571 16475 16458 16460>,
			<16873 16705 16581 16479 16460 16460>,
			<16968 16738 16589 16483 16462 16460>,
			<17048 16766 16594 16486 16463 16460>,
			<17084 16777 16596 16488 16463 16460>,
			<17085 16775 16594 16488 16463 16461>,
			<17086 16772 16589 16488 16462 16461>,
			<17088 16772 16589 16488 16462 16462>,
			<17095 16776 16592 16487 16464 16463>,
			<17106 16782 16597 16486 16467 16464>,
			<17126 16791 16606 16489 16470 16466>,
			<17154 16805 16620 16495 16474 16468>,
			<17180 16831 16637 16502 16478 16471>,
			<17211 16887 16661 16514 16484 16476>,
			<17229 16923 16685 16526 16491 16480>,
			<17123 16899 16709 16540 16498 16485>,
			<16919 16845 16730 16554 16507 16490>,
			<16838 16792 16724 16570 16521 16501>,
			<16815 16732 16666 16589 16546 16526>,
			<16797 16683 16608 16600 16561 16540>,
			<16771 16654 16575 16561 16531 16518>,
			<16745 16633 16549 16498 16484 16480>,
			<16721 16615 16537 16482 16470 16468>,
			<16696 16600 16530 16479 16466 16464>,
			<16681 16587 16527 16478 16464 16462>,
			<16684 16572 16526 16480 16467 16464>,
			<16693 16558 16525 16483 16474 16467>,
			<16697 16549 16525 16487 16480 16472>,
			<16700 16543 16524 16493 16487 16480>,
			<16702 16541 16524 16499 16494 16488>,
			<16705 16543 16518 16505 16502 16497>,
			<16709 16549 16508 16510 16510 16505>,
			<16712 16557 16506 16510 16511 16506>,
			<16717 16567 16508 16510 16508 16502>,
			<16722 16581 16512 16509 16503 16497>,
			<16724 16602 16520 16496 16489 16487>,
			<16725 16628 16532 16478 16471 16476>,
			<16725 16641 16542 16474 16468 16474>,
			<16720 16648 16549 16474 16469 16474>,
			<16714 16652 16555 16475 16469 16475>,
			<16711 16645 16560 16480 16471 16477>,
			<16709 16632 16563 16485 16472 16478>,
			<16717 16629 16562 16479 16457 16457>,
			<16737 16634 16570 16479 16453 16449>,
			<16739 16654 16576 16484 16464 16468>,
			<16735 16668 16591 16493 16482 16502>,
			<16750 16712 16616 16511 16519 16539>,
			<16765 16754 16660 16541 16553 16567>,
			<16810 16801 16708 16566 16548 16540>,
			<16947 16845 16732 16518 16472 16473>,
			<17249 16867 16720 16506 16471 16472>,
			<18129 16980 16763 16519 16473 16473>,
			<22275 17825 16870 16554 16485 16481>,
			<22275 17825 16870 16554 16485 16481>,
			<22275 17825 16870 16554 16485 16481>;
	};

	qcom,pc-temp-y5-lut {
		qcom,lut-col-legend = <(-10) 0 10 25 40 50>;
		qcom,lut-row-legend = <10000 9800 9600 9400 9200 9000>,
			<8800 8600 8400 8200 8000 7800>,
			<7600 7400 7200 7000 6800 6600>,
			<6400 6200 6000 5800 5600 5400>,
			<5200 5000 4800 4600 4400 4200>,
			<4000 3800 3600 3400 3200 3000>,
			<2800 2600 2400 2200 2000 1800>,
			<1600 1400 1200 1000 900 800>,
			<700 600 500 400 300 200>,
			<100 0>;
		qcom,lut-data = <15672 16868 19331 18962 19589 18849>,
			<16012 17418 19026 18506 19112 19037>,
			<16344 17753 18719 17517 18506 19110>,
			<16662 17926 18431 16355 17906 19091>,
			<16964 17990 18184 15383 17446 19002>,
			<17245 18000 18002 14964 17262 18867>,
			<17481 17879 17901 14951 17343 18475>,
			<17717 17619 17814 14949 17468 17921>,
			<18119 17335 17573 15132 17447 17604>,
			<18904 16921 16913 16075 17168 17331>,
			<19386 16682 16308 16693 16828 17077>,
			<18175 16847 15848 16468 16492 16863>,
			<16073 17130 15432 15978 16099 16639>,
			<16099 17165 15315 15424 15648 16311>,
			<19558 16980 15278 14653 15058 15794>,
			<22134 16845 15265 14234 14751 15509>,
			<21565 19038 16566 14376 14788 15623>,
			<20478 22909 19025 14755 14894 15883>,
			<20358 23702 20628 15688 15289 16198>,
			<21499 22741 21892 18417 16715 16661>,
			<22392 22015 22486 20132 17714 17102>,
			<20587 22164 22003 20064 17822 17434>,
			<16758 22473 21195 19899 17855 17726>,
			<14722 22631 20985 19683 17972 18019>,
			<13687 22900 21040 19339 18315 18415>,
			<13082 23093 21166 19095 18525 18629>,
			<12810 23384 21379 19137 17754 18158>,
			<12603 23901 21650 19288 16550 17203>,
			<12571 23368 21906 19368 16320 16379>,
			<12720 18787 22361 19650 16371 15513>,
			<12923 15109 22688 19938 16458 15072>,
			<13132 15217 22773 20110 16840 15309>,
			<13381 15737 22807 20318 17539 15877>,
			<13568 16470 22627 20778 18249 16628>,
			<13776 17941 21628 21936 19088 17865>,
			<13982 18991 20823 22751 19749 19011>,
			<14173 18375 20636 22835 20189 20027>,
			<14365 16927 20486 22782 20533 21084>,
			<14403 16194 20310 22586 20664 21868>,
			<14185 15943 20005 21784 20700 23002>,
			<13958 15711 19625 21024 20705 23656>,
			<13889 15270 19111 20074 21133 23508>,
			<13802 14870 18620 19242 21493 23093>,
			<13580 14883 18420 19440 20024 20305>,
			<13462 14707 17316 19048 18728 19381>,
			<13632 14164 15585 18104 17205 17846>,
			<13789 14450 15466 17513 19050 17151>,
			<14121 14501 16804 18071 17840 16262>,
			<14360 15225 17385 19376 17387 16227>,
			<14234 16758 19000 19805 17068 15446>,
			<13480 17209 18009 19412 18802 16981>,
			<11909 16735 16102 20038 17559 16611>,
			<10262 13970 14004 18859 18717 16553>,
			<9299 10694 13567 21163 20340 21977>,
			<9299 10694 13567 21163 20340 21977>,
			<9299 10694 13567 21163 20340 21977>;
	};

	qcom,pc-temp-y6-lut {
		qcom,lut-col-legend = <(-10) 0 10 25 40 50>;
		qcom,lut-row-legend = <10000 9800 9600 9400 9200 9000>,
			<8800 8600 8400 8200 8000 7800>,
			<7600 7400 7200 7000 6800 6600>,
			<6400 6200 6000 5800 5600 5400>,
			<5200 5000 4800 4600 4400 4200>,
			<4000 3800 3600 3400 3200 3000>,
			<2800 2600 2400 2200 2000 1800>,
			<1600 1400 1200 1000 900 800>,
			<700 600 500 400 300 200>,
			<100 0>;
		qcom,lut-data = <5636 5289 5141 5023 4997 4991>,
			<5652 5302 5142 5024 4997 4991>,
			<5670 5312 5143 5024 4998 4992>,
			<5685 5319 5143 5024 4998 4993>,
			<5697 5324 5143 5025 4999 4994>,
			<5702 5325 5143 5025 5000 4994>,
			<5698 5323 5142 5026 5000 4995>,
			<5693 5318 5140 5026 5001 4995>,
			<5692 5315 5139 5027 5002 4996>,
			<5693 5313 5138 5029 5003 4997>,
			<5694 5312 5137 5031 5004 4998>,
			<5687 5313 5138 5033 5006 4999>,
			<5674 5315 5141 5034 5007 5000>,
			<5673 5319 5145 5037 5009 5002>,
			<5687 5330 5151 5039 5010 5003>,
			<5697 5337 5157 5042 5013 5005>,
			<5667 5330 5163 5047 5015 5007>,
			<5610 5315 5168 5053 5019 5010>,
			<5591 5298 5166 5059 5024 5015>,
			<5588 5276 5146 5064 5032 5021>,
			<5585 5258 5126 5066 5036 5025>,
			<5575 5249 5113 5052 5024 5015>,
			<5562 5243 5103 5029 5004 4997>,
			<5559 5240 5099 5022 4999 4993>,
			<5563 5238 5098 5021 4998 4992>,
			<5570 5236 5097 5020 4997 4992>,
			<5585 5237 5097 5021 4998 4992>,
			<5608 5237 5099 5023 4999 4993>,
			<5633 5237 5100 5024 5000 4994>,
			<5659 5238 5102 5027 5003 4996>,
			<5688 5238 5103 5029 5005 4998>,
			<5720 5245 5103 5031 5009 5001>,
			<5756 5261 5103 5033 5012 5004>,
			<5795 5279 5103 5034 5012 5004>,
			<5839 5300 5106 5035 5011 5004>,
			<5887 5323 5111 5035 5010 5003>,
			<5938 5348 5118 5033 5006 5000>,
			<5993 5375 5127 5028 5000 4997>,
			<6051 5406 5137 5027 5000 4996>,
			<6110 5439 5147 5028 5001 4998>,
			<6174 5475 5159 5030 5002 4999>,
			<6242 5511 5173 5033 5003 5000>,
			<6317 5550 5188 5035 5005 5001>,
			<6406 5604 5205 5036 5000 4993>,
			<6516 5676 5229 5038 5000 4992>,
			<6603 5741 5237 5041 5006 5002>,
			<6647 5783 5254 5046 5015 5013>,
			<6774 5858 5287 5055 5026 5025>,
			<6931 5952 5326 5068 5037 5034>,
			<7233 6073 5369 5077 5035 5023>,
			<7904 6239 5398 5059 5010 5003>,
			<9226 6499 5443 5060 5011 5005>,
			<12121 7138 5580 5069 5016 5008>,
			<19163 8994 5922 5094 5024 5018>,
			<19163 8994 5922 5094 5024 5018>,
			<19163 8994 5922 5094 5024 5018>;
	};

};
